VERSION "HIPBNYYYYYYYYYYYYYYYYYYYYYYYYYYYYYYYYYYYYY/4/%%%/4/'%**4YYY///"

NS_ :

BS_:

BU_:

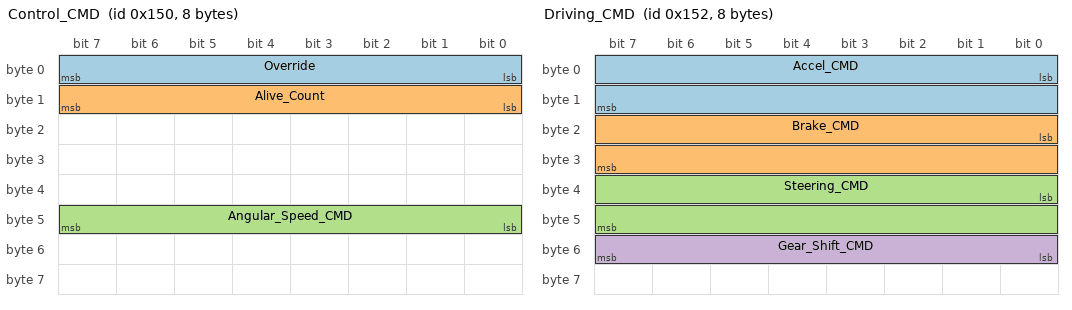
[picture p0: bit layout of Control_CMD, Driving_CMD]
BO_ 336 Control_CMD: 8 Vector__XXX
 SG_ Override : 0|8@1+ (1,0) [0|1] "" Vector__XXX
 SG_ Alive_Count : 8|8@1+ (1,0) [0|255] "" Vector__XXX
 SG_ Angular_Speed_CMD : 40|8@1+ (1,0) [0|255] "" Vector__XXX

BO_ 338 Driving_CMD: 8 Vector__XXX
 SG_ Accel_CMD : 0|16@1+ (1,0) [650|3400] "" Vector__XXX
 SG_ Brake_CMD : 16|16@1+ (1,0) [0|17000] "" Vector__XXX
 SG_ Steering_CMD : 32|16@1- (1,0) [-520|520] "deg" Vector__XXX
 SG_ Gear_Shift_CMD : 48|8@1+ (1,0) [0|7] "" Vector__XXX

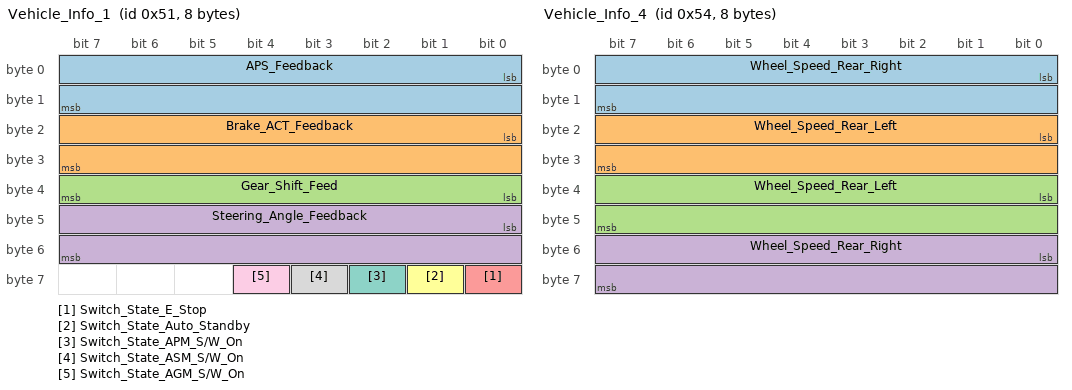
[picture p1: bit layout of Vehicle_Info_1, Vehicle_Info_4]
BO_ 81 Vehicle_Info_1: 8 Vector__XXX
 SG_ APS_Feedback : 0|16@1+ (1,0) [0|3800] "" Vector__XXX
 SG_ Brake_ACT_Feedback : 16|16@1+ (1,0) [0|35000] "" Vector__XXX
 SG_ Gear_Shift_Feed : 32|8@1+ (1,0) [0|7] "" Vector__XXX
 SG_ Steering_Angle_Feedback : 40|16@1- (-0.1,0) [-540|540] "" Vector__XXX
 SG_ Switch_State_E_Stop : 56|1@1+ (1,0) [0|1] "" Vector__XXX
 SG_ Switch_State_Auto_Standby : 57|1@1+ (1,0) [0|2] "" Vector__XXX
 SG_ Switch_State_APM_S/W_On : 58|1@1+ (1,0) [0|4] "" Vector__XXX
 SG_ Switch_State_ASM_S/W_On : 59|1@1+ (1,0) [0|8] "" Vector__XXX
 SG_ Switch_State_AGM_S/W_On : 60|1@1+ (1,0) [0|22] "" Vector__XXX

BO_ 82 Vehicle_Info_2: 8 Vector__XXX
 SG_ Override_Feedback : 0|1@1+ (1,0) [0|6] "" Vector__XXX
 SG_ Vehicle_Speed : 8|16@1+ (0.1,0) [0|255] "km/h" Vector__XXX

BO_ 83 Vehicle_Info_3: 8 Vector__XXX
 SG_ RPM : 0|16@1+ (1,0) [0|8000] "" Vector__XXX

BO_ 84 Vehicle_Info_4: 8 Vector__XXX
 SG_ Wheel_Speed_Rear_Right : 0|16@1+ (0.1,0) [0|255] "km/h" Vector__XXX
 SG_ Wheel_Speed_Rear_Left : 16|16@1+ (0.1,0) [0|255] "km/h" Vector__XXX
 SG_ Wheel_Speed_Rear_Left : 32|16@1+ (0.1,0) [0|255] "km/h" Vector__XXX
 SG_ Wheel_Speed_Rear_Right : 48|16@1+ (0.1,0) [0|255] "km/h" Vector__XXX

BA_DEF_  "BusType" STRING ;
BA_DEF_DEF_  "BusType" "";
BA_ "BusType" "CAN";
VAL_ 336 Override 0 "Overide_On" 1 "Override_Off" ;
VAL_ 338 Gear_Shift_CMD 0 "Parking" 5 "Driving" 6 "Neutral" 7 "Reverse" ;
VAL_ 81 Gear_Shift_Feed 0 "Parking" 5 "Driving" 6 "Neutral" 7 "Reverse" ;
VAL_ 81 Switch_State_E_Stop 0 "Off" 1 "Open" ;
VAL_ 81 Switch_State_Auto_Standby 0 "Manual" 2 "Auto" ;
VAL_ 81 Switch_State_APM_S/W_On 0 "Manual" 4 "Auto" ;
VAL_ 81 Switch_State_ASM_S/W_On 0 "Manual" 8 "Auto" ;
VAL_ 81 Switch_State_AGM_S/W_On 0 "Manual" 22 "Auto" ;
VAL_ 82 Override_Feedback 0 "Manual" 1 "Auto" 2 "Steer" 3 "Accel" 4 "Brake" 5 "Sensor" 6 "E_Stop" ;
